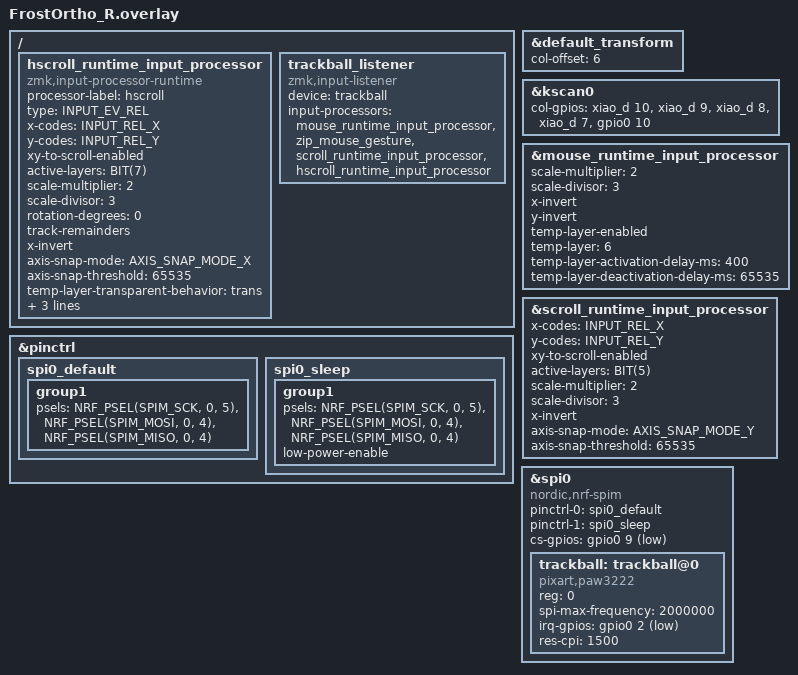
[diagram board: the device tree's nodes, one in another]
#include "FrostOrtho.dtsi"
#include <input/processors.dtsi>
#include <dt-bindings/zmk/input_transform.h>
#include <zephyr/dt-bindings/input/input-event-codes.h>
#include <input/processors/runtime-input-processor.dtsi>
#include <dt-bindings/zmk/runtime_input_processor.h>
#include <zephyr/dt-bindings/dt-util.h>
#include <behaviors/battery_history_request.dtsi>
#include <mouse-gesture.dtsi>

&default_transform {
    col-offset = <6>;
};

&kscan0 {
    col-gpios
        = <&xiao_d 10 GPIO_ACTIVE_HIGH>
        , <&xiao_d 9 GPIO_ACTIVE_HIGH> 
        , <&xiao_d 8 GPIO_ACTIVE_HIGH> 
        , <&xiao_d 7 GPIO_ACTIVE_HIGH> 
        , <&gpio0 10 GPIO_ACTIVE_HIGH>
        ;
};

// ========================================
// トラックボール（DYA Studio から変更可能）
// ここの値は初期値。DYA Studio で保存した設定があればそちらが優先される
// ========================================

// カーソル移動 + AML
&mouse_runtime_input_processor {
    scale-multiplier = <2>; // カーソル移動量2/3倍
    scale-divisor = <3>;
    x-invert; // カーソルの移動方向調整
    y-invert;

    // AML（自動マウスレイヤー）
    // MOUSEレイヤーで &trans 以外が割り当てられたキーと修飾キーでは AML から離脱しない
    temp-layer-enabled;
    temp-layer = <6>;
    temp-layer-activation-delay-ms = <400>; // キー入力後400ms以内はAMLに切り替わらない
    temp-layer-deactivation-delay-ms = <65535>; // タイムアウト時間（最大65535ms）
};

// 縦スクロール（レイヤー5）
&scroll_runtime_input_processor {
    x-codes = <INPUT_REL_X>; // トラックボールのXYを受けてスクロールに変換する
    y-codes = <INPUT_REL_Y>;
    xy-to-scroll-enabled;
    active-layers = <BIT(5)>;
    scale-multiplier = <2>; // スクロール量2/3倍
    scale-divisor = <3>;
    x-invert; // スクロール方向調整
    axis-snap-mode = <AXIS_SNAP_MODE_Y>; // 縦方向のみ
    axis-snap-threshold = <65535>; // 横方向へのロック解除をしない
};

/ {
    // 横スクロール（レイヤー7）
    hscroll_runtime_input_processor: hscroll_runtime_input_processor {
        compatible = "zmk,input-processor-runtime";
        processor-label = "hscroll";
        type = <INPUT_EV_REL>;
        x-codes = <INPUT_REL_X>;
        y-codes = <INPUT_REL_Y>;
        xy-to-scroll-enabled;
        active-layers = <BIT(7)>;
        scale-multiplier = <2>; // スクロール量2/3倍
        scale-divisor = <3>;
        rotation-degrees = <0>;
        track-remainders;
        x-invert; // スクロール方向調整
        axis-snap-mode = <AXIS_SNAP_MODE_X>; // 横方向のみ
        axis-snap-threshold = <65535>; // 縦方向へのロック解除をしない

        temp-layer-transparent-behavior = <&trans>;
        temp-layer-kp-behavior = <&kp>;
        temp-layer-keep-keycodes = <LEFT_CONTROL LEFT_SHIFT LEFT_ALT LEFT_GUI RIGHT_CONTROL RIGHT_SHIFT RIGHT_ALT RIGHT_GUI>;

        #input-processor-cells = <0>;
    };
};

/ {
    trackball_listener: trackball_listener {
        status = "okay";
        compatible = "zmk,input-listener";
        device = <&trackball>;

        input-processors = <
            &mouse_runtime_input_processor
            &zip_mouse_gesture // マウスジェスチャー（方向調整後に置くこと）
            &scroll_runtime_input_processor
            &hscroll_runtime_input_processor
        >;
    };
};

&pinctrl {
    spi0_default: spi0_default {
        group1 {
            psels = <NRF_PSEL(SPIM_SCK, 0, 5)>,
                <NRF_PSEL(SPIM_MOSI, 0, 4)>,
                <NRF_PSEL(SPIM_MISO, 0, 4)>;
        };
    };

    spi0_sleep: spi0_sleep {
        group1 {
            psels = <NRF_PSEL(SPIM_SCK, 0, 5)>,
                <NRF_PSEL(SPIM_MOSI, 0, 4)>,
                <NRF_PSEL(SPIM_MISO, 0, 4)>;
            low-power-enable;
        };
    };
};

&spi0 {
    status = "okay";
    compatible = "nordic,nrf-spim";
    pinctrl-0 = <&spi0_default>;
    pinctrl-1 = <&spi0_sleep>;
    pinctrl-names = "default", "sleep";
    cs-gpios = <&gpio0 9 GPIO_ACTIVE_LOW>;

    trackball: trackball@0 {
        status = "okay";
        compatible = "pixart,paw3222";
        reg = <0>;
        spi-max-frequency = <2000000>;
        irq-gpios = <&gpio0 2 (GPIO_ACTIVE_LOW | GPIO_PULL_UP)>;
        res-cpi = <1500>;
    };
};


